AUTOSAR XML (schema 4-2-1)
package /RootP_ASWC_M740
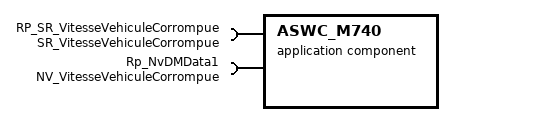
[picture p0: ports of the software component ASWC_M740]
  application sw component type ASWC_M740
    require port RP_SR_VitesseVehiculeCorrompue: required-interface=SR_VitesseVehiculeCorrompue
    require port Rp_NvDMData1: required-com-specs=[data1U32, data2U16], required-interface=NV_VitesseVehiculeCorrompue
package /RootP_Composition
  composition sw component type Compo_VSM
    component Instance_ASWC_M740: type=ASWC_M740
